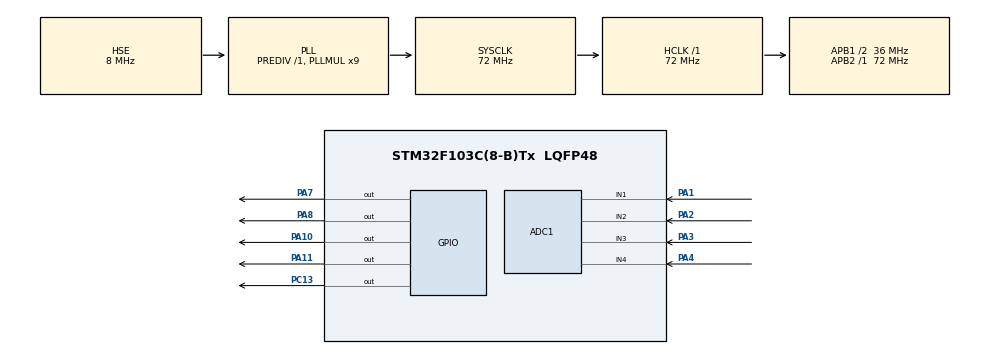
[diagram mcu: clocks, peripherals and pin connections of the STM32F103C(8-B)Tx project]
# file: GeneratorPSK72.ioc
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ADC1.Channel-0\#ChannelRegularConversion=ADC_CHANNEL_1
ADC1.Channel-1\#ChannelRegularConversion=ADC_CHANNEL_2
ADC1.Channel-2\#ChannelRegularConversion=ADC_CHANNEL_3
ADC1.Channel-3\#ChannelRegularConversion=ADC_CHANNEL_4
ADC1.ContinuousConvMode=ENABLE
ADC1.NbrOfConversion=4
ADC1.NbrOfConversionFlag=1
ADC1.Rank-0\#ChannelRegularConversion=1
ADC1.Rank-1\#ChannelRegularConversion=2
ADC1.Rank-2\#ChannelRegularConversion=3
ADC1.Rank-3\#ChannelRegularConversion=4
ADC1.SamplingTime-0\#ChannelRegularConversion=ADC_SAMPLETIME_7CYCLES_5
ADC1.SamplingTime-1\#ChannelRegularConversion=ADC_SAMPLETIME_7CYCLES_5
ADC1.SamplingTime-2\#ChannelRegularConversion=ADC_SAMPLETIME_7CYCLES_5
ADC1.SamplingTime-3\#ChannelRegularConversion=ADC_SAMPLETIME_7CYCLES_5
ADC1.master=1
Dma.ADC1.0.Direction=DMA_PERIPH_TO_MEMORY
Dma.ADC1.0.Instance=DMA1_Channel1
Dma.ADC1.0.MemDataAlignment=DMA_MDATAALIGN_HALFWORD
Dma.ADC1.0.MemInc=DMA_MINC_ENABLE
Dma.ADC1.0.Mode=DMA_CIRCULAR
Dma.ADC1.0.PeriphDataAlignment=DMA_PDATAALIGN_HALFWORD
Dma.ADC1.0.PeriphInc=DMA_PINC_DISABLE
Dma.ADC1.0.Priority=DMA_PRIORITY_LOW
Dma.Request0=ADC1
Mcu.Family=STM32F1
Mcu.Name=STM32F103C(8-B)Tx
Mcu.Package=LQFP48
NVIC.ADC1_2_IRQn=true\:2\:0\:true\:false\:true\:true\:true
NVIC.DMA1_Channel1_IRQn=true\:3\:0\:true\:false\:true\:false\:true
NVIC.PriorityGroup=NVIC_PRIORITYGROUP_4
NVIC.RCC_IRQn=true\:0\:0\:false\:false\:true\:true\:false
NVIC.TIM3_IRQn=true\:0\:0\:false\:false\:true\:true\:false
PA1.Signal=ADCx_IN1
PA10.Signal=GPIO_Output
PA11.Signal=GPIO_Output
PA13.Mode=Serial_Wire
PA13.Signal=SYS_JTMS-SWDIO
PA14.Mode=Serial_Wire
PA14.Signal=SYS_JTCK-SWCLK
PA2.Signal=ADCx_IN2
PA3.Signal=ADCx_IN3
PA4.Signal=ADCx_IN4
PA7.GPIO_Speed=GPIO_SPEED_FREQ_HIGH
PA7.PinState=GPIO_PIN_SET
PA7.Signal=GPIO_Output
PA8.GPIO_Speed=GPIO_SPEED_FREQ_HIGH
PA8.PinState=GPIO_PIN_SET
PA8.Signal=GPIO_Output
PC13-TAMPER-RTC.Signal=GPIO_Output
PD0-OSC_IN.Mode=HSE-External-Oscillator
PD0-OSC_IN.Signal=RCC_OSC_IN
PD1-OSC_OUT.Mode=HSE-External-Oscillator
PD1-OSC_OUT.Signal=RCC_OSC_OUT
ProjectManager.HeapSize=0x200
ProjectManager.StackSize=0x400
ProjectManager.TargetToolchain=SW4STM32
RCC.ADCPresc=RCC_ADCPCLK2_DIV6
RCC.AHBFreq_Value=72000000
RCC.APB1CLKDivider=RCC_HCLK_DIV2
RCC.APB1Freq_Value=36000000
RCC.APB1TimFreq_Value=72000000
RCC.APB2Freq_Value=72000000
RCC.APB2TimFreq_Value=72000000
RCC.HCLKFreq_Value=72000000
RCC.PLLMUL=RCC_PLL_MUL9
RCC.PLLSourceVirtual=RCC_PLLSOURCE_HSE
RCC.SYSCLKFreq_VALUE=72000000
RCC.SYSCLKSource=RCC_SYSCLKSOURCE_PLLCLK
RCC.USBFreq_Value=72000000
SH.ADCx_IN1.0=ADC1_IN1,IN1
SH.ADCx_IN2.0=ADC1_IN2,IN2
SH.ADCx_IN3.0=ADC1_IN3,IN3
SH.ADCx_IN4.0=ADC1_IN4,IN4
TIM3.AutoReloadPreload=TIM_AUTORELOAD_PRELOAD_ENABLE
TIM3.Channel-Output\ Compare1\ No\ Output=TIM_CHANNEL_1
TIM3.Period=500
TIM3.Pulse-Output\ Compare1\ No\ Output=250
VP_TIM3_VS_ClockSourceINT.Mode=Internal
VP_TIM3_VS_no_output1.Mode=Output Compare1 No Output
board=custom

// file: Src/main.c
/* USER CODE BEGIN Header */
/**
  ******************************************************************************
  * @file           : main.c
  * @brief          : Main program body
  ******************************************************************************
  * @attention
  *
  * <h2><center>&copy; Copyright (c) 2020 STMicroelectronics.
  * All rights reserved.</center></h2>
  *
  * This software component is licensed by ST under BSD 3-Clause license,
  * the "License"; You may not use this file except in compliance with the
  * License. You may obtain a copy of the License at:
  *                        opensource.org/licenses/BSD-3-Clause
  *
  ******************************************************************************
  */
/* USER CODE END Header */

#include "main.h"

/* USER CODE BEGIN Includes */
#include "kernel.h"
/* USER CODE END Includes */

ADC_HandleTypeDef hadc1;
DMA_HandleTypeDef hdma_adc1;

TIM_HandleTypeDef htim3;

void SystemClock_Config(void);
static void MX_GPIO_Init(void);
static void MX_TIM3_Init(void);
static void MX_DMA_Init(void);
static void MX_ADC1_Init(void);

int main(void)
{

  /* MCU Configuration--------------------------------------------------------*/

  /* Reset of all peripherals, Initializes the Flash interface and the Systick. */
  HAL_Init();

  /* Configure the system clock */
  SystemClock_Config();

  /* Initialize all configured peripherals */
  MX_GPIO_Init();
  MX_TIM3_Init();
  MX_DMA_Init();
  MX_ADC1_Init();
  /* USER CODE BEGIN 2 */
  Kernel_Init(&htim3, &hadc1, &hdma_adc1);
  /* USER CODE END 2 */

  /* Infinite loop */
  /* USER CODE BEGIN WHILE */
  Kernel_Task();
  while (1)
  {
    /* USER CODE END WHILE */

  }
}

void SystemClock_Config(void)
{
  RCC_OscInitTypeDef RCC_OscInitStruct = {0};
  RCC_ClkInitTypeDef RCC_ClkInitStruct = {0};
  RCC_PeriphCLKInitTypeDef PeriphClkInit = {0};

  /** Initializes the CPU, AHB and APB busses clocks
  */
  RCC_OscInitStruct.OscillatorType = RCC_OSCILLATORTYPE_HSE;
  RCC_OscInitStruct.HSEState = RCC_HSE_ON;
  RCC_OscInitStruct.HSEPredivValue = RCC_HSE_PREDIV_DIV1;
  RCC_OscInitStruct.HSIState = RCC_HSI_ON;
  RCC_OscInitStruct.PLL.PLLState = RCC_PLL_ON;
  RCC_OscInitStruct.PLL.PLLSource = RCC_PLLSOURCE_HSE;
  RCC_OscInitStruct.PLL.PLLMUL = RCC_PLL_MUL9;
  if (HAL_RCC_OscConfig(&RCC_OscInitStruct) != HAL_OK)
  {
    Error_Handler();
  }
  /** Initializes the CPU, AHB and APB busses clocks
  */
  RCC_ClkInitStruct.ClockType = RCC_CLOCKTYPE_HCLK|RCC_CLOCKTYPE_SYSCLK
                              |RCC_CLOCKTYPE_PCLK1|RCC_CLOCKTYPE_PCLK2;
  RCC_ClkInitStruct.SYSCLKSource = RCC_SYSCLKSOURCE_PLLCLK;
  RCC_ClkInitStruct.AHBCLKDivider = RCC_SYSCLK_DIV1;
  RCC_ClkInitStruct.APB1CLKDivider = RCC_HCLK_DIV2;
  RCC_ClkInitStruct.APB2CLKDivider = RCC_HCLK_DIV1;

  if (HAL_RCC_ClockConfig(&RCC_ClkInitStruct, FLASH_LATENCY_2) != HAL_OK)
  {
    Error_Handler();
  }
  PeriphClkInit.PeriphClockSelection = RCC_PERIPHCLK_ADC;
  PeriphClkInit.AdcClockSelection = RCC_ADCPCLK2_DIV6;
  if (HAL_RCCEx_PeriphCLKConfig(&PeriphClkInit) != HAL_OK)
  {
    Error_Handler();
  }
}

static void MX_ADC1_Init(void)
{

  ADC_ChannelConfTypeDef sConfig = {0};

  /** Common config
  */
  hadc1.Instance = ADC1;
  hadc1.Init.ScanConvMode = ADC_SCAN_ENABLE;
  hadc1.Init.ContinuousConvMode = ENABLE;
  hadc1.Init.DiscontinuousConvMode = DISABLE;
  hadc1.Init.ExternalTrigConv = ADC_SOFTWARE_START;
  hadc1.Init.DataAlign = ADC_DATAALIGN_RIGHT;
  hadc1.Init.NbrOfConversion = 4;
  if (HAL_ADC_Init(&hadc1) != HAL_OK)
  {
    Error_Handler();
  }
  /** Configure Regular Channel
  */
  sConfig.Channel = ADC_CHANNEL_1;
  sConfig.Rank = ADC_REGULAR_RANK_1;
  sConfig.SamplingTime = ADC_SAMPLETIME_7CYCLES_5;
  if (HAL_ADC_ConfigChannel(&hadc1, &sConfig) != HAL_OK)
  {
    Error_Handler();
  }
  /** Configure Regular Channel
  */
  sConfig.Channel = ADC_CHANNEL_2;
  sConfig.Rank = ADC_REGULAR_RANK_2;
  if (HAL_ADC_ConfigChannel(&hadc1, &sConfig) != HAL_OK)
  {
    Error_Handler();
  }
  /** Configure Regular Channel
  */
  sConfig.Channel = ADC_CHANNEL_3;
  sConfig.Rank = ADC_REGULAR_RANK_3;
  if (HAL_ADC_ConfigChannel(&hadc1, &sConfig) != HAL_OK)
  {
    Error_Handler();
  }
  /** Configure Regular Channel
  */
  sConfig.Channel = ADC_CHANNEL_4;
  sConfig.Rank = ADC_REGULAR_RANK_4;
  if (HAL_ADC_ConfigChannel(&hadc1, &sConfig) != HAL_OK)
  {
    Error_Handler();
  }

}

static void MX_TIM3_Init(void)
{

  TIM_ClockConfigTypeDef sClockSourceConfig = {0};
  TIM_MasterConfigTypeDef sMasterConfig = {0};
  TIM_OC_InitTypeDef sConfigOC = {0};

  htim3.Instance = TIM3;
  htim3.Init.Prescaler = 0;
  htim3.Init.CounterMode = TIM_COUNTERMODE_UP;
  htim3.Init.Period = 500;
  htim3.Init.ClockDivision = TIM_CLOCKDIVISION_DIV1;
  htim3.Init.AutoReloadPreload = TIM_AUTORELOAD_PRELOAD_ENABLE;
  if (HAL_TIM_Base_Init(&htim3) != HAL_OK)
  {
    Error_Handler();
  }
  sClockSourceConfig.ClockSource = TIM_CLOCKSOURCE_INTERNAL;
  if (HAL_TIM_ConfigClockSource(&htim3, &sClockSourceConfig) != HAL_OK)
  {
    Error_Handler();
  }
  if (HAL_TIM_OC_Init(&htim3) != HAL_OK)
  {
    Error_Handler();
  }
  sMasterConfig.MasterOutputTrigger = TIM_TRGO_RESET;
  sMasterConfig.MasterSlaveMode = TIM_MASTERSLAVEMODE_DISABLE;
  if (HAL_TIMEx_MasterConfigSynchronization(&htim3, &sMasterConfig) != HAL_OK)
  {
    Error_Handler();
  }
  sConfigOC.OCMode = TIM_OCMODE_TIMING;
  sConfigOC.Pulse = 250;
  sConfigOC.OCPolarity = TIM_OCPOLARITY_HIGH;
  sConfigOC.OCFastMode = TIM_OCFAST_DISABLE;
  if (HAL_TIM_OC_ConfigChannel(&htim3, &sConfigOC, TIM_CHANNEL_1) != HAL_OK)
  {
    Error_Handler();
  }

}

static void MX_DMA_Init(void)
{

  /* DMA controller clock enable */
  __HAL_RCC_DMA1_CLK_ENABLE();

  /* DMA interrupt init */
  /* DMA1_Channel1_IRQn interrupt configuration */
  HAL_NVIC_SetPriority(DMA1_Channel1_IRQn, 3, 0);
  HAL_NVIC_EnableIRQ(DMA1_Channel1_IRQn);

}

static void MX_GPIO_Init(void)
{
  GPIO_InitTypeDef GPIO_InitStruct = {0};

  /* GPIO Ports Clock Enable */
  __HAL_RCC_GPIOC_CLK_ENABLE();
  __HAL_RCC_GPIOD_CLK_ENABLE();
  __HAL_RCC_GPIOA_CLK_ENABLE();

  /*Configure GPIO pin Output Level */
  HAL_GPIO_WritePin(GPIOC, GPIO_PIN_13, GPIO_PIN_RESET);

  /*Configure GPIO pin Output Level */
  HAL_GPIO_WritePin(GPIOA, GPIO_PIN_7|GPIO_PIN_8, GPIO_PIN_SET);

  /*Configure GPIO pin Output Level */
  HAL_GPIO_WritePin(GPIOA, GPIO_PIN_10|GPIO_PIN_11, GPIO_PIN_RESET);

  /*Configure GPIO pin : PC13 */
  GPIO_InitStruct.Pin = GPIO_PIN_13;
  GPIO_InitStruct.Mode = GPIO_MODE_OUTPUT_PP;
  GPIO_InitStruct.Pull = GPIO_NOPULL;
  GPIO_InitStruct.Speed = GPIO_SPEED_FREQ_LOW;
  HAL_GPIO_Init(GPIOC, &GPIO_InitStruct);

  /*Configure GPIO pins : PA7 PA8 */
  GPIO_InitStruct.Pin = GPIO_PIN_7|GPIO_PIN_8;
  GPIO_InitStruct.Mode = GPIO_MODE_OUTPUT_PP;
  GPIO_InitStruct.Pull = GPIO_NOPULL;
  GPIO_InitStruct.Speed = GPIO_SPEED_FREQ_HIGH;
  HAL_GPIO_Init(GPIOA, &GPIO_InitStruct);

  /*Configure GPIO pins : PA10 PA11 */
  GPIO_InitStruct.Pin = GPIO_PIN_10|GPIO_PIN_11;
  GPIO_InitStruct.Mode = GPIO_MODE_OUTPUT_PP;
  GPIO_InitStruct.Pull = GPIO_NOPULL;
  GPIO_InitStruct.Speed = GPIO_SPEED_FREQ_LOW;
  HAL_GPIO_Init(GPIOA, &GPIO_InitStruct);

}

void Error_Handler(void)
{
}

/************************ (C) COPYRIGHT STMicroelectronics *****END OF FILE****/
